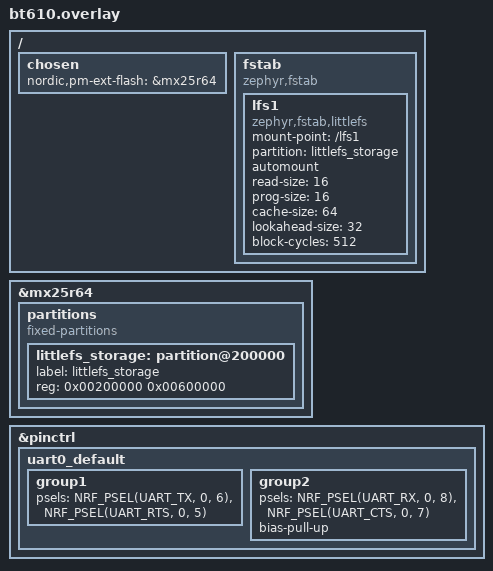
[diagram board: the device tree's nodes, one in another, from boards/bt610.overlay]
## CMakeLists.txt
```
cmake_minimum_required(VERSION 3.13.1)

set(FWK_APP_ID_FILE_LIST
    ${CMAKE_SOURCE_DIR}/src/framework_config/framework_ids_list.h
)

set(FWK_APP_MSG_FILE_LIST
    ${CMAKE_SOURCE_DIR}/src/framework_config/framework_msg_codes_list.h
)
set(mcuboot_CONF_FILE
    ${CMAKE_SOURCE_DIR}/mcuboot_bt610.conf
)
set(mcuboot_ROOT_APP_DIR
    ${CMAKE_SOURCE_DIR}/src
)
set(mcuboot_ROOT_PROJECT_APP_DIR
    ${CMAKE_SOURCE_DIR}
)
set(PM_STATIC_YML_FILE
    ${CMAKE_SOURCE_DIR}/pm_static.sb.bt610.yml
)
set(b0_OVERLAY_CONFIG
    ${CMAKE_SOURCE_DIR}/b0_bt610.conf
)
set(b0_DTC_OVERLAY_FILE
    ${CMAKE_SOURCE_DIR}/boards/bootloader.${BOARD}.overlay
)

set(mcuboot_DTC_OVERLAY_FILE
    ${CMAKE_SOURCE_DIR}/boards/bootloader.${BOARD}.overlay
)

# The component-generated files for attributes
set(ATTR_CUSTOM_PATH_BASE ${CMAKE_SOURCE_DIR}/components/attributes/bt610)

# Version information generation
# Generate build ID based on UTC timestamp
string(TIMESTAMP build_time "%s" UTC)
set(APP_VERSION_BUILD ${build_time})
set(gen_dir ${CMAKE_BINARY_DIR}/zephyr/include/generated/app)
set(ver_file ${gen_dir}/app_version.h)
configure_file(${CMAKE_SOURCE_DIR}/src/version/app_version.h.in ${ver_file})

# Get application version
file(READ ${ver_file} ver)
string(REGEX MATCH "APP_VERSION_MAJOR ([0-9]+)" _ ${ver})
set(ver_major ${CMAKE_MATCH_1})
string(REGEX MATCH "APP_VERSION_MINOR ([0-9]+)" _ ${ver})
set(ver_minor ${CMAKE_MATCH_1})
string(REGEX MATCH "APP_VERSION_PATCH ([0-9]+)" _ ${ver})
set(ver_patch ${CMAKE_MATCH_1})
set(app_version ${ver_major}.${ver_minor}.${ver_patch}+${build_time})
message("app version: ${app_version}")

# Set application version for mcuboot
set(mcuboot_ver_conf ${CMAKE_BINARY_DIR}/generated_mcuboot_image_version.conf)
set(MCUBOOT_IMAGE_VERSION ${app_version})

# This configuration file will get automatically merged when building.
# No need to append to OVERLAY_CONFIG
configure_file(${CMAKE_SOURCE_DIR}/src/version/mcuboot_image_version.conf.in ${mcuboot_ver_conf})

find_package(Zephyr REQUIRED HINTS $ENV{ZEPHYR_BASE})
project(bt610_dm_firmware)

# Build the API
execute_process(
    COMMAND
    ${PYTHON_EXECUTABLE}
    ${CMAKE_SOURCE_DIR}/../modules/lib/laird_connect/attributes/generator/api.py
    ${CMAKE_SOURCE_DIR}
    bt610
    WORKING_DIRECTORY ${CMAKE_SOURCE_DIR}
    RESULT_VARIABLE api_result
)

if(NOT "${api_result}" STREQUAL 0)
    message(FATAL_ERROR "Failed to build API")
endif()

include_directories(${CMAKE_SOURCE_DIR}/include)
include_directories(${CMAKE_SOURCE_DIR}/src/framework_config)
include_directories(${CMAKE_SOURCE_DIR}/src/version)
target_include_directories(app PRIVATE ${gen_dir})
zephyr_include_directories(${CMAKE_SOURCE_DIR}/memfault)

target_sources(app PRIVATE
    ${CMAKE_SOURCE_DIR}/src/AdcBt6.c
    ${CMAKE_SOURCE_DIR}/src/Advertisement.c
    ${CMAKE_SOURCE_DIR}/src/BleTask.c
    ${CMAKE_SOURCE_DIR}/src/BspSupport.c
    ${CMAKE_SOURCE_DIR}/src/ControlTask.c
    ${CMAKE_SOURCE_DIR}/src/EventTask.c
    ${CMAKE_SOURCE_DIR}/src/LEDs.c
    ${CMAKE_SOURCE_DIR}/src/main.c
    ${CMAKE_SOURCE_DIR}/src/NonInit.c
    ${CMAKE_SOURCE_DIR}/src/SensorTask.c
    ${CMAKE_SOURCE_DIR}/src/UserInterfaceTask.c
    ${CMAKE_SOURCE_DIR}/src/Flags.c
    ${ATTR_CUSTOM_PATH_BASE}/src/attr_custom_validator.c
)

if(CONFIG_FS_MGMT_FILE_ACCESS_HOOK)
    target_sources(app PRIVATE
        ${CMAKE_SOURCE_DIR}/src/FileAccess.c
    )
endif()

if(CONFIG_MCUMGR_CMD_PRODUCTION_MGMT)
    target_sources(app PRIVATE
        ${CMAKE_SOURCE_DIR}/src/production_mgmt.c
    )
endif()

if(CONFIG_TEST_MENU)
    target_sources(app PRIVATE
        ${CMAKE_SOURCE_DIR}/src/TestMenu.c
    )
endif()
```

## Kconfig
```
# Copyright (c) 2020 Laird Connectivity
# SPDX-License-Identifier: Apache-2.0

menuconfig USER_APPLICATION
     bool "Config User Application"
	 default y

if USER_APPLICATION

config LAIRD_CONNECTIVITY_DEBUG
    bool
    default n

config JSON_BRACKET_BUFFER_SIZE
    int "The maximum size JSON message that can be processed"
    default 1536
    help
        This applies to sensor messages received over Bluetooth.

config ATTR_SAVE_DELAY_MS
    int "Time (in ms) before saving attributes to filesystem to cache other data to write"
    default 30000
    range 1000 3600000

config UART_SHUTOFF
    bool "Enables shutting the main UART off to conserve power"
    default y

config FILE_ACCESS_LOG_LEVEL
    int "File access log level for reading/writing files over SMP"
    range 0 4
    default 0

config ATTR_SHELL_ALLOW_DEBUG_COMMANDS
    bool "Enables shell functions that can modify, dump and load data"
    help
        This should not be enabled for production builds.

menuconfig MINIMUM_FIRMWARE_VERSION_FOTA_CHECK
    bool "Enable minimum firmware version FOTA check"
    default y

config MINIMUM_FIRMWARE_VERSION_MAJOR
    int "Major firmware version (a.x.x) which is the minimum allowed for FOTA"
    range 0 255
    default 1
    depends on MINIMUM_FIRMWARE_VERSION_FOTA_CHECK

config MINIMUM_FIRMWARE_VERSION_MINOR
    int "Minor firmware version (x.b.x) which is the minimum allowed for FOTA"
    range 0 255
    default 28
    depends on MINIMUM_FIRMWARE_VERSION_FOTA_CHECK

config MINIMUM_FIRMWARE_VERSION_REVISION
    int "Revision firmware version (x.x.c) which is the minimum allowed for FOTA"
    range 0 65535
    default 0
    depends on MINIMUM_FIRMWARE_VERSION_FOTA_CHECK

config MAX_SETTINGS_FILE_SIZE
    int "Maximum size of settings file before removing to save space"
    range 0 4096
    default 1024
    depends on SETTINGS_FS
    help
        A setting of 0 will not purge the file, purge size must be greater than
	256 to be valid.

endif # USER_APPLICATION

rsource "src/Kconfig"

source "Kconfig.zephyr"
```

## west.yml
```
manifest:
  remotes:
    - name: JsmnRepo
      url-base: https://github.com/zserge
    - name: LairdProdEng
      url-base: git@git.devops.rfpros.com:prod_eng
    - name: LairdZephyrPublic
      url-base: git@git.devops.rfpros.com:zephyr_public

  # Please add items below based on alphabetical order.
  # These dependencies may need updating if new features are added to the firmware.
  projects:
    - name: framework_zephyr
      path: modules/framework
      revision: b9a4603436a34d61120b68a10a6cbc74d1e6a3fd
      remote: LairdProdEng
    - name: jsmn
      path: modules/jsmn
      revision: 7b6858a5855299d173c5ab2b46e611bf9961cbef
      remote: JsmnRepo      
    - name: zephyr_boards
      path: zephyr/boards/arm
      revision: master
      remote: LairdZephyrPublic
    - name: zephyr_lib
      path: modules/zephyr_lib
      revision: master
      remote: LairdProdEng      

  self:
    path: root
```

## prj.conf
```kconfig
CONFIG_MCUBOOT_IMAGE_VERSION="2.0.4"

CONFIG_BOOT_BANNER=n

# Enable power management
CONFIG_PM=y
CONFIG_PM_DEVICE=y
CONFIG_PM_DEVICE_RUNTIME=y
CONFIG_PM_DEVICE_RUNTIME_EXCLUSIVE=n

# System stack and heap sizes
CONFIG_SYSTEM_WORKQUEUE_STACK_SIZE=8192
CONFIG_HEAP_MEM_POOL_SIZE=16384
CONFIG_MAIN_STACK_SIZE=4096

# System clock
CONFIG_SYSTEM_CLOCK_WAIT_FOR_STABILITY=y

# Safe reboot
CONFIG_REBOOT=y

# BSP
CONFIG_I2C=y
CONFIG_ADC=y
CONFIG_ADC_NRFX_SAADC=y
CONFIG_GPIO=y

# Floating point support
CONFIG_NEWLIB_LIBC=y
CONFIG_NEWLIB_LIBC_FLOAT_PRINTF=y
# Allow thread-safe FPU for thermistor calculations.
CONFIG_FPU=y
CONFIG_FPU_SHARING=y

# BLE
CONFIG_BT=y
CONFIG_BT_HCI=y
CONFIG_BT_HCI_VS_EXT=y
CONFIG_BT_DEBUG_LOG=n
CONFIG_BT_GAP_PERIPHERAL_PREF_PARAMS=y
CONFIG_BT_PERIPHERAL_PREF_MIN_INT=6
CONFIG_BT_PERIPHERAL_PREF_MAX_INT=150
CONFIG_BT_PERIPHERAL_PREF_LATENCY=2
CONFIG_BT_PERIPHERAL_PREF_TIMEOUT=500
CONFIG_BT_DEVICE_NAME_GATT_WRITABLE=n
CONFIG_BT_SMP=y
CONFIG_BT_MAX_PAIRED=10
CONFIG_BT_PERIPHERAL=y
CONFIG_BT_FIXED_PASSKEY=n
CONFIG_BT_BONDABLE=n
CONFIG_BT_DEVICE_NAME="BT610"
CONFIG_BT_DEVICE_NAME_DYNAMIC=y
# Generic sensor
CONFIG_BT_DEVICE_APPEARANCE=1344
CONFIG_BT_GATT_DYNAMIC_DB=y
CONFIG_BT_REMOTE_VERSION=y
CONFIG_BT_LL_SOFTDEVICE=y
CONFIG_BT_LL_SOFTDEVICE_MULTIROLE=y
CONFIG_BT_MAX_CONN=2
CONFIG_BT_HCI_TX_STACK_SIZE=2048
CONFIG_BT_BUF_ACL_TX_SIZE=251
CONFIG_BT_BUF_ACL_RX_SIZE=260
CONFIG_BT_BUF_EVT_RX_SIZE=255
CONFIG_BT_L2CAP_TX_MTU=260
CONFIG_BT_CTLR_DATA_LENGTH_MAX=251
CONFIG_BT_BUF_ACL_TX_COUNT=5
CONFIG_BT_BUF_ACL_RX_COUNT=5
CONFIG_BT_BUF_EVT_RX_COUNT=5
CONFIG_BT_BUF_EVT_DISCARDABLE_COUNT=5
CONFIG_BT_BUF_CMD_TX_COUNT=5
CONFIG_BT_CONN_TX_MAX=12
CONFIG_BT_L2CAP_TX_BUF_COUNT=12
CONFIG_BT_L2CAP_TX_FRAG_COUNT=3
CONFIG_BT_HCI_TX_STACK_SIZE_WITH_PROMPT=y
CONFIG_BT_HCI_TX_STACK_SIZE=2048
CONFIG_BT_CTLR=y
CONFIG_BT_CTLR_TX_PWR_PLUS_8=y
CONFIG_BT_CTLR_TX_PWR_DYNAMIC_CONTROL=y
# Allow Coded PHY (requires Nordic Bluetooth host)
CONFIG_BT_CTLR_PHY_CODED=y
CONFIG_BT_EXT_ADV=y
CONFIG_BT_CTLR_ADV_EXT=y
CONFIG_BT_USER_PHY_UPDATE=y
# Nordic Softdevice configuration
CONFIG_BT_CTLR_SDC_RX_STACK_SIZE=2048
CONFIG_BT_CTLR_SDC_MAX_CONN_EVENT_LEN_DEFAULT=820000
# Disable auto DLE due to bug with pre-4.2 devices - Bug #19725
CONFIG_BT_AUTO_DATA_LEN_UPDATE=n
# Additions for DM
CONFIG_BT_GATT_CLIENT=y
CONFIG_BT_GATT_DM=y
CONFIG_BT_DFU_SMP=y
CONFIG_BT_USER_DATA_LEN_UPDATE=y
CONFIG_BT_RX_STACK_SIZE=4096

# Console
CONFIG_LOG=y
CONFIG_LOG_DEFAULT_LEVEL=4
CONFIG_LOG_BUFFER_SIZE=4096
CONFIG_LOG_PROCESS_THREAD_STACK_SIZE=4096
CONFIG_LOG_SPEED=y
CONFIG_LOG_TRACE_SHORT_TIMESTAMP=n
CONFIG_LOG_TIMESTAMP_64BIT=y
CONFIG_LOG_BACKEND_FS=y
CONFIG_LOG_BACKEND_FS_DIR="/lfs1/logs"
CONFIG_LOG_BACKEND_FS_FILE_SIZE=128000
CONFIG_LOG_BACKEND_FS_FILES_LIMIT=8

# Command line shell
CONFIG_SHELL=y
CONFIG_SHELL_HISTORY=n
CONFIG_KERNEL_SHELL=y
CONFIG_SHELL_STACK_SIZE=3072
CONFIG_SHELL_THREAD_PRIORITY_OVERRIDE=y
# Change priority to be higher than logging thread to avoid log messages not showing at boot
CONFIG_SHELL_THREAD_PRIORITY=13
CONFIG_DEVMEM_SHELL=n
CONFIG_FLASH_SHELL=n
CONFIG_LCZ_SHELL_LOGIN=y
CONFIG_SHELL_LOGIN_INIT_PRIORITY=75
CONFIG_SHELL_LOGIN_INIT_USING_ATTRIBUTES=y
CONFIG_SHELL_PROMPT_UART="login: "
CONFIG_SHELL_CMD_ROOT="login"
CONFIG_LCZ_SHELL_SCRIPT_RUNNER=y
CONFIG_SHELL_BACKEND_DUMMY=y

# LCZ Message Framework
CONFIG_FRAMEWORK=y
CONFIG_FWK_ASSERT_ENABLED=y
CONFIG_FWK_AUTO_GENERATE_FILES=y
CONFIG_BUFFER_POOL_SIZE=16384
CONFIG_BUFFER_POOL_STATS=y
CONFIG_BUFFER_POOL_SHELL=y
CONFIG_SYSTEM_MESSAGE_TASK=y

# Flash storage
CONFIG_MPU_ALLOW_FLASH_WRITE=y
CONFIG_FLASH=y
CONFIG_FLASH_PAGE_LAYOUT=y
CONFIG_FLASH_MAP=y

# Device settings
CONFIG_SETTINGS=y
# Prefix must match CONFIG_SETTINGS_MOUNT_POINT
CONFIG_SETTINGS_MOUNT_POINT="/lfs1"
CONFIG_SETTINGS_FS_DIR="/lfs1/settings"
CONFIG_SETTINGS_FS_FILE="/lfs1/settings/run"

# QSPI (MX25R64)
CONFIG_NORDIC_QSPI_NOR=y
CONFIG_NORDIC_QSPI_NOR_FLASH_LAYOUT_PAGE_SIZE=4096
CONFIG_NORDIC_QSPI_NOR_STACK_WRITE_BUFFER_SIZE=16

# MCUBOOT
CONFIG_BOOTLOADER_MCUBOOT=y
CONFIG_SECURE_BOOT=y
CONFIG_BUILD_S1_VARIANT=y
CONFIG_NRF_APPROTECT_LOCK=y
CONFIG_LCZ_APPROTECT=y
CONFIG_MCUBOOT_IMG_MANAGER=y
# Turn off for development
# Bug 22277 - Remove comment around CONFIG_LCZ_APPROTECT_STARTUP
# CONFIG_LCZ_APPROTECT_STARTUP=y

# MCUMGR
CONFIG_MCUMGR=y
CONFIG_MCUMGR_SMP_SHELL=y
CONFIG_MCUBOOT_SHELL_ERASE_ENABLED=n
CONFIG_MCUMGR_SMP_SHELL_MTU=512
CONFIG_MCUMGR_SMP_SHELL_RX_BUF_COUNT=4
CONFIG_MCUMGR_BUF_SIZE=1210
CONFIG_MCUMGR_BUF_COUNT=8
# Enable the Bluetooth (unauthenticated) mcumgr transport.
CONFIG_MCUMGR_SMP_BT=y
CONFIG_MCUMGR_CMD_IMG_MGMT=y
CONFIG_MCUMGR_CMD_OS_MGMT=y
CONFIG_MCUMGR_CMD_PRODUCTION_MGMT=y
CONFIG_STATS=y
CONFIG_MCUMGR_CMD_STAT_MGMT=y
CONFIG_MCUMGR_CMD_SHELL_MGMT=y
CONFIG_OS_MGMT_MCUMGR_PARAMS=y
CONFIG_MCUMGR_SMP_REASSEMBLY_BT=y

# File system
# Enable the LittleFS file system.
CONFIG_FILE_SYSTEM=y
CONFIG_FILE_SYSTEM_LITTLEFS=y
CONFIG_FILE_SYSTEM_UTILITIES=y
CONFIG_FSU_MOUNT_POINT="/lfs1"
CONFIG_FSU_LOG_LEVEL=3
CONFIG_FILE_SYSTEM_MAX_FILE_NAME=64
CONFIG_FSU_SHELL_ALLOW_CHANGE=n
CONFIG_FSU_CHECKSUM=y
CONFIG_FSU_CHECKSUM_CHUNK_SIZE=512
CONFIG_FSU_ENCRYPTED_FILES=y
CONFIG_FILE_ACCESS_LOG_LEVEL=3
CONFIG_FSU_ENCRYPTED_FILES_INIT_PRIORITY=65
CONFIG_LCZ_MCUMGR_CMD_FS_MGMT=y
CONFIG_LCZ_FS_MGMT_MAX_FILE_SIZE_4GB=y
CONFIG_LCZ_FS_MGMT_FILE_ACCESS_HOOK=y
CONFIG_LCZ_FS_MGMT_CHECKSUM_HASH=y
CONFIG_LCZ_FS_MGMT_HASH_SHA256=y
CONFIG_FSU_HASH=y
CONFIG_FILE_SYSTEM_SHELL=y

# Security
CONFIG_NRF_SECURITY=y

# MBEDTLS
CONFIG_MBEDTLS=y
CONFIG_MBEDTLS_BUILTIN=n
CONFIG_MBEDTLS_TLS_LIBRARY=y
CONFIG_MBEDTLS_LEGACY_CRYPTO_C=y
CONFIG_MBEDTLS_SSL_IN_CONTENT_LEN=4096
CONFIG_MBEDTLS_SSL_OUT_CONTENT_LEN=4096
CONFIG_MBEDTLS_ENABLE_HEAP=y
CONFIG_MBEDTLS_HEAP_SIZE=16384
# Disable unused ciphers.
# NOTE: Commented lines below mean we are allowing those ciphers
CONFIG_MBEDTLS_KEY_EXCHANGE_PSK_ENABLED=n
CONFIG_MBEDTLS_KEY_EXCHANGE_DHE_PSK_ENABLED=n
CONFIG_MBEDTLS_KEY_EXCHANGE_ECDHE_PSK_ENABLED=n
CONFIG_MBEDTLS_KEY_EXCHANGE_RSA_PSK_ENABLED=n
CONFIG_MBEDTLS_KEY_EXCHANGE_RSA_ENABLED=n
CONFIG_MBEDTLS_KEY_EXCHANGE_DHE_RSA_ENABLED=n
CONFIG_MBEDTLS_KEY_EXCHANGE_ECDHE_RSA_ENABLED=n
# CONFIG_MBEDTLS_KEY_EXCHANGE_ECDHE_ECDSA_ENABLED=n
# CONFIG_MBEDTLS_KEY_EXCHANGE_ECDH_ECDSA_ENABLED=n
CONFIG_MBEDTLS_KEY_EXCHANGE_ECDH_RSA_ENABLED=n
CONFIG_MBEDTLS_KEY_EXCHANGE_ECJPAKE_ENABLED=n
# Disable CBC, it is not secure
CONFIG_PSA_WANT_ALG_CBC_NO_PADDING=n
CONFIG_PSA_WANT_ALG_CBC_PKCS7=n
CONFIG_MBEDTLS_CIPHER_MODE_CBC=n
# Disable unused hash algorithms
CONFIG_PSA_WANT_ALG_SHA_384=n
CONFIG_PSA_WANT_ALG_SHA_512=n
CONFIG_PSA_WANT_ALG_MD5=n
CONFIG_MBEDTLS_SHA384_C=n
CONFIG_MBEDTLS_SHA512_C=n

# LCZ modules
CONFIG_LCZ=y

# LCZ BLE wrapper
CONFIG_LCZ_BT=y

# LCZ QRTC
CONFIG_LCZ_QRTC=y
CONFIG_LCZ_QRTC_SHELL=y
CONFIG_LCZ_QRTC_SHELL_ENABLE_WRITE=n

# LCZ Exit override
CONFIG_LCZ_RESET_ON_EXIT=y

# LCZ Param file
CONFIG_LCZ_PARAM_FILE=y
CONFIG_LCZ_PARAM_FILE_ENCRYPTED=y
CONFIG_LCZ_SENSOR_ADV_FORMAT=y
CONFIG_LCZ_MCUMGR_WRAPPER=y
CONFIG_LCZ_NO_INIT_RAM_VAR=y
CONFIG_ATTRIBUTE_MGMT_FACTORY_RESET=y

# LCZ LED module
CONFIG_LCZ_LED=y
CONFIG_LCZ_NUMBER_OF_LEDS=2
CONFIG_LCZ_LED_CUSTOM_ON_OFF=n

# LCZ Watchdog support
CONFIG_WATCHDOG=y
CONFIG_WDT_NRFX=y
CONFIG_NRFX_WDT0=y
CONFIG_LCZ_WDT=y

# LCZ reset reason utility
CONFIG_LCZ_NRF_RESET_REASON=y

# LCZ Attributes
CONFIG_LCZ_KVP=y
CONFIG_ATTR=y
CONFIG_ATTR_BROADCAST=y
CONFIG_ATTR_ENCRYPTED=y
CONFIG_ATTR_SHELL=y
CONFIG_ATTR_DEFERRED_SAVE=y
CONFIG_MCUMGR_CMD_ATTRIBUTE_MGMT=y
CONFIG_ATTR_LOAD_FEEDBACK=y
CONFIG_ATTR_CUSTOM_VALIDATOR=y
CONFIG_ATTR_SHELL=y
CONFIG_ATTR_SHOW_FMT="[%03u] %-35s"
CONFIG_ATTR_FILE_NAME="enc/attr.txt"

# LCZ hardware unique key
CONFIG_HW_UNIQUE_KEY=y
CONFIG_HW_UNIQUE_KEY_RANDOM=y
CONFIG_LCZ_HW_KEY=y

# LCZ Locking component
CONFIG_LOCKING=y

# LCS Software Reset management
CONFIG_LCZ_SOFTWARE_RESET=y

# zcbor
CONFIG_ZCBOR=y

# Thread Debug
CONFIG_THREAD_NAME=y
CONFIG_THREAD_MAX_NAME_LEN=16
CONFIG_INIT_STACKS=y
CONFIG_THREAD_ANALYZER=y

# Stack protection options that should always be enabled
CONFIG_MPU_STACK_GUARD=y

# Debug options that should be enabled for debugging
CONFIG_ASSERT=n
CONFIG_STACK_SENTINEL=n
CONFIG_EXTRA_EXCEPTION_INFO=y
CONFIG_NULL_POINTER_EXCEPTION_DETECTION_MPU=y
CONFIG_USE_SEGGER_RTT=y

# Application level options
CONFIG_LOG_LEVEL_BLE_TASK=3
CONFIG_UI_TASK_LOG_LEVEL=3
CONFIG_BSP_LOG_LEVEL=3
CONFIG_UI_LED_TEST_ON_RESET=y
CONFIG_TEST_MENU=y
CONFIG_HEARTBEAT_SECONDS=60
CONFIG_SENSOR_TASK_LOG_LEVEL=3

# PKI authentication and management
CONFIG_LCZ_PKI_AUTH=y
CONFIG_LCZ_PKI_AUTH_SMP_PERIPHERAL=y
CONFIG_LCZ_SENSOR_ADV_ENC=y

# LWM2M
CONFIG_EVENTFD=y
CONFIG_LWM2M=y
CONFIG_LWM2M_LOG_LEVEL_INF=y
CONFIG_HTTP_PARSER_URL=y
CONFIG_LWM2M_COAP_BLOCK_SIZE=512
CONFIG_LWM2M_ENGINE_STACK_SIZE=8192
# LwM2M lifetime of 10 minutes instead of 30 seconds
CONFIG_LWM2M_ENGINE_DEFAULT_LIFETIME=600
# Observation notifications normally no faster than every minute
CONFIG_LWM2M_SERVER_DEFAULT_PMIN=60

# Client device manager
CONFIG_LCZ_BLE_CLIENT_DM=y
CONFIG_LCZ_BLE_CLIENT_DM_INIT_ATTRIBUTES=y
CONFIG_LCZ_BLE_CLIENT_CONTROL_QRTC=y

# Main LwM2M Client
CONFIG_LCZ_LWM2M_CLIENT=y
CONFIG_LCZ_LWM2M_CLIENT_LOG_LEVEL_DBG=y
CONFIG_LCZ_LWM2M_CLIENT_INIT_ATTRIBUTES=y
CONFIG_LCZ_LWM2M_CLIENT_DEVICE_INIT_ATTRIBUTES=y
CONFIG_LCZ_LWM2M_TRANSPORT_BLE_PERIPHERAL=y
CONFIG_LCZ_LWM2M_TRANSPORT_BLE_MAX_PACKET=1200
CONFIG_LCZ_LWM2M_CLIENT_SHELL=y

# Firmware update
CONFIG_LCZ_LWM2M_FW_UPDATE=y
CONFIG_LWM2M_SWMGMT_PACKAGE_URI_LEN=256
CONFIG_DFU_TARGET=y
CONFIG_IMG_ERASE_PROGRESSIVELY=y
CONFIG_LCZ_LWM2M_FW_UPDATE_INIT_ATTRIBUTES=y
CONFIG_LWM2M_FIRMWARE_UPDATE_PULL_COAP_PROXY_SUPPORT=y
CONFIG_LCZ_LWM2M_FW_UPDATE_SHELL=y

# File system management
CONFIG_LCZ_LWM2M_FS_MANAGEMENT=y

# Connection Monitor
CONFIG_LCZ_LWM2M_CONN_MON=y
CONFIG_LWM2M_CONN_MON_BEARER_MAX=2

# Networking
CONFIG_NETWORKING=y
CONFIG_NET_NATIVE=n
CONFIG_NET_IPV6=n

# LwM2M Telemetry Configuration
CONFIG_LWM2M_IPSO_SUPPORT=y
CONFIG_LCZ_LWM2M_UTIL=y
CONFIG_LCZ_LWM2M_UTIL_CONFIG_DATA=y
CONFIG_LCZ_LWM2M_UTIL_LOG_LEVEL_DBG=y
CONFIG_LCZ_LWM2M_TEMPERATURE=y
CONFIG_LWM2M_IPSO_TEMP_SENSOR=y
CONFIG_LWM2M_IPSO_TEMP_SENSOR_INSTANCE_COUNT=4
CONFIG_LCZ_LWM2M_FILL_LEVEL=y
CONFIG_LWM2M_IPSO_FILLING_SENSOR=y
CONFIG_LWM2M_IPSO_FILLING_SENSOR_INSTANCE_COUNT=4
CONFIG_LCZ_LWM2M_CURRENT=y
CONFIG_LWM2M_IPSO_CURRENT_SENSOR=y
CONFIG_LWM2M_IPSO_CURRENT_SENSOR_INSTANCE_COUNT=4
CONFIG_LCZ_LWM2M_PRESSURE=y
CONFIG_LWM2M_IPSO_PRESSURE_SENSOR=y
CONFIG_LWM2M_IPSO_PRESSURE_SENSOR_INSTANCE_COUNT=4
```

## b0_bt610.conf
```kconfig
# WARNING: To maintain the integrity of secure boot,
# enable CONFIG_DISABLE_FLASH_PATCH in production.
# CONFIG_DISABLE_FLASH_PATCH=y
CONFIG_HW_UNIQUE_KEY_LOAD=y
CONFIG_RESET_ON_FATAL_ERROR=n
CONFIG_REBOOT=y
CONFIG_I2C=n

CONFIG_SECURE_BOOT_DEBUG=n
CONFIG_CONSOLE=n
CONFIG_UART_CONSOLE=n
CONFIG_BOOT_BANNER=n
CONFIG_LOG=n

CONFIG_HW_STACK_PROTECTION=n
```

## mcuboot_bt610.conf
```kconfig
# Laird Connectivity BT6 mcuboot configuration
# Enables CC310 with ECDSA-p256 and no debugging
CONFIG_BOOT_VALIDATE_SLOT0=y

CONFIG_SIZE_OPTIMIZATIONS=y

CONFIG_BOOT_BANNER=n

CONFIG_CONSOLE_HANDLER=n
CONFIG_DEBUG=n

CONFIG_MAIN_STACK_SIZE=10240
CONFIG_MBEDTLS_CFG_FILE="mcuboot-mbedtls-cfg.h"

# Do not erase all flash when flashing mcuboot
CONFIG_ZEPHYR_TRY_MASS_ERASE=n

### Default to ECDSA
CONFIG_BOOT_SIGNATURE_TYPE_ECDSA_P256=y
CONFIG_BOOT_ECDSA_CC310=y
CONFIG_BOOT_SIGNATURE_KEY_FILE="root-ec-p256.pem"
CONFIG_NRF_CC310_BL=y

### We never want Zephyr's copy of tinycrypt.  If tinycrypt is needed,
### MCUboot has its own copy in tree.
# CONFIG_TINYCRYPT is not set
# CONFIG_TINYCRYPT_ECC_DSA is not set
# CONFIG_TINYCRYPT_SHA256 is not set

CONFIG_FLASH=y

# nrf52840 with QSPI
CONFIG_MULTITHREADING=y
CONFIG_NORDIC_QSPI_NOR=y
CONFIG_NORDIC_QSPI_NOR_FLASH_LAYOUT_PAGE_SIZE=4096
CONFIG_NORDIC_QSPI_NOR_STACK_WRITE_BUFFER_SIZE=16
CONFIG_BOOT_MAX_IMG_SECTORS=256
CONFIG_MPU_ALLOW_FLASH_WRITE=y

CONFIG_BOOT_SWAP_USING_MOVE=y
CONFIG_BOOT_BANNER=n
CONFIG_SERIAL=n
CONFIG_CONSOLE=n
CONFIG_UART_CONSOLE=n
CONFIG_STDOUT_CONSOLE=n
CONFIG_PRINTK=n
CONFIG_EARLY_CONSOLE=n
CONFIG_ASSERT_VERBOSE=n

CONFIG_LCZ=y
CONFIG_LCZ_NO_INIT_RAM_VAR=y
CONFIG_LCZ_LED=y
CONFIG_LCZ_NUMBER_OF_LEDS=2

# WARNING: To maintain the integrity of secure boot,
# enable CONFIG_DISABLE_FLASH_PATCH in production.
# Bug 22275 - enable CONFIG_DISABLE_FLASH_PATCH
# CONFIG_DISABLE_FLASH_PATCH=y
CONFIG_FW_INFO=y
# set mcuboot version
CONFIG_FW_INFO_FIRMWARE_VERSION=1
CONFIG_RESET_ON_FATAL_ERROR=n
CONFIG_REBOOT=y
```

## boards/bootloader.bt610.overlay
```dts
/delete-node/ &uart1;
```

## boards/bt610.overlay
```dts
/*
 * Copyright (c) 2021 Nordic Semiconductor ASA
 * Copyright (c) 2022 Laird Connectivity LLC
 *
 * SPDX-License-Identifier: LicenseRef-Nordic-5-Clause
 */

/delete-node/ &lfs_partition;

/ {
	chosen {
		/* required for partition manager to use external flash */
		nordic,pm-ext-flash = &mx25r64;
	};

	fstab {
		compatible = "zephyr,fstab";
		lfs1: lfs1 {
			compatible = "zephyr,fstab,littlefs";
			mount-point = "/lfs1";
			partition = <&littlefs_storage>;
			automount;
			read-size = <16>;
			prog-size = <16>;
			cache-size = <64>;
			lookahead-size = <32>;
			block-cycles = <512>;
		};
	};
};

&mx25r64 {
	partitions {
		compatible = "fixed-partitions";
		#address-cells = <1>;
		#size-cells = <1>;

		littlefs_storage: partition@200000 {
			label = "littlefs_storage";
			reg = <0x00200000 0x00600000>;
		};
	};
};

/delete-node/ &uart1;
/delete-node/ &uart0_default;

&pinctrl {
	uart0_default: uart0_default {
		group1 {
			psels = <NRF_PSEL(UART_TX, 0, 6)>,
					<NRF_PSEL(UART_RTS, 0, 5)>;
		};
		group2 {
			psels = <NRF_PSEL(UART_RX, 0, 8)>,
					<NRF_PSEL(UART_CTS, 0, 7)>;
			bias-pull-up;
		};
	};
};
```

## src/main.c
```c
/* main.c - Application main entry point */

/*
 * Copyright (c) 2019-2023 Laird Connectivity
 *
 * SPDX-License-Identifier: Apache-2.0
 */
#include <zephyr/logging/log.h>
LOG_MODULE_REGISTER(main, LOG_LEVEL_DBG);
#include <zephyr/zephyr.h>
#include <version.h>
#ifdef CONFIG_ATTR
#include <attr.h>
#endif
#ifdef CONFIG_LCZ_LWM2M_CLIENT
#include <lcz_lwm2m_client.h>
#endif
#ifdef CONFIG_LCZ_LWM2M_FW_UPDATE
#include <lcz_lwm2m_fw_update.h>
#endif
#include "app_version.h"
#ifdef CONFIG_SHELL_BACKEND_SERIAL
#include <zephyr/shell/shell_uart.h>
#endif
#include <zephyr/drivers/uart.h>
#include "ControlTask.h"
#include "BspSupport.h"

/**************************************************************************************************/
/* Local Constant, Macro and Type Definitions                                                     */
/**************************************************************************************************/
#define PKG_NAME_PREFIX "lc_dm"
#define PKG_NAME PKG_NAME_PREFIX "-" CONFIG_BOARD "-"

void main(void)
{
#ifdef CONFIG_SHELL_BACKEND_SERIAL
	/* Disable log output by default on the UART console.
	 * Re-enable logging using the 'log go' cmd.
	 * LCZ_SHELL_LOGIN selects SHELL_START_OBSCURED which disables log output before main().
	 */
#ifdef CONFIG_ATTR
	if (attr_get_bool(ATTR_ID_log_on_boot) == false)
#endif
	{
		log_backend_deactivate(shell_backend_uart_get_ptr()->log_backend->backend);
	}
#endif

#ifdef CONFIG_LCZ_LWM2M_CLIENT
	(void)lcz_lwm2m_client_set_device_firmware_version(APP_VERSION_STRING);
	(void)lcz_lwm2m_client_set_software_version(KERNEL_VERSION_STRING);
#endif
#ifdef CONFIG_LCZ_LWM2M_FW_UPDATE
	(void)lcz_lwm2m_fw_update_set_pkg_name(PKG_NAME);
#endif
	BSP_Init();
	ControlTask_Initialize();
	ControlTask_Thread();

	LOG_INF("BT610 DM Firmware v%s [%s]", APP_VERSION_STRING, CONFIG_BOARD);
}
```

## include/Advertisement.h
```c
/**
 * @file Advertisement.h
 * @brief
 *
 * Copyright (c) 2020 Laird Connectivity
 *
 * SPDX-License-Identifier: Apache-2.0
 */
#ifndef __ADVERTISEMENT_H__
#define __ADVERTISEMENT_H__

/******************************************************************************/
/* Includes                                                                   */
/******************************************************************************/

#ifdef __cplusplus
extern "C" {
#endif

/******************************************************************************/
/* Global Constants, Macros and Type Definitions                              */
/******************************************************************************/
typedef struct {
	SensorEvent_t event;
	uint32_t id;
} SensorMsg_t;

/******************************************************************************/
/* Global Data Definitions                                                    */
/******************************************************************************/

/******************************************************************************/
/* Global Function Prototypes                                                 */
/******************************************************************************/
/**
 * @brief Setup of the different advertisment PHY types
 */
int Advertisement_Init(void);

/**
 * @brief Stops the device from advertising 
 */
int Advertisement_End(void);

/**
 * @brief Starts advertising with the PHY that is enabled
 */
int Advertisement_Start(void);

/**
 * @brief Will force the the coded PHY(Extended advertisment) to begin 
 *  when status is set to true
 *
 * @param status This will enable or disable the coded PHY
 */
void Advertisement_ExtendedSet(bool status);

/**
 * @brief This function will update bytes that have changed in advertisment
 *
 * @param sensor_event There are fields in the advert for events, and this is that data
 *
 * @retval negative error code, 0 on success
 */
int Advertisement_Update(SensorMsg_t *sensor_event);

/**
 * @brief The advertisment interval has been set elsewhere and needs 
 * parameter changed and read from the attribute
 *
 * @retval negative error code, 0 on success
 */
int Advertisement_IntervalUpdate(void);

/**
 * @brief This will set the interval back to what default was and 
 * not change interval attribute
 *
 * @retval negative error code, 0 on success
 */
int Advertisement_IntervalDefault(void);

/**
 * @brief This is only used for the test menue to create a simulated event
 *
 * @param status event number that will be created
 */
void TestEventMsg(uint16_t event);

#ifdef __cplusplus
}
#endif

#endif /* __ADVERTISEMENT_H__ */
```

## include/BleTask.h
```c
/**
 * @file BleTask.h
 * @brief
 *
 * Copyright (c) 2020 Laird Connectivity
 *
 * SPDX-License-Identifier: Apache-2.0
 */
#ifndef __BLE_TASK_H__
#define __BLE_TASK_H__

/******************************************************************************/
/* Includes                                                                   */
/******************************************************************************/
#include <zephyr/types.h>
#include <stddef.h>

#ifdef __cplusplus
extern "C" {
#endif

/******************************************************************************/
/* Global Constants, Macros and Type Definitions                              */
/******************************************************************************/

/******************************************************************************/
/* Global Data Definitions                                                    */
/******************************************************************************/

/******************************************************************************/
/* Global Function Prototypes                                                 */
/******************************************************************************/
/**
 * @brief
 *
 * @param
 * @param
 *
 * @retval
 */
void BleTask_Initialize(void);

/**
 * @brief Returns if there is an active connection
 *
 * @retval true if there is an active connection, false otherwise
 */
bool ble_is_connected(void);

/**
 * @brief Returns if the last connection was made used coded PHY
 *
 * @retval true if LE coded, false otherwise
 */
bool ble_conn_last_was_le_coded(void);

#ifdef __cplusplus
}
#endif

#endif /* __BLE_TASK_H__ */
```

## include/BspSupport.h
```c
/**
 * @file BspSupport.h
 *
 * Copyright (c) 2020-2023 Laird Connectivity
 *
 * SPDX-License-Identifier: Apache-2.0
 */
#ifndef __BSP_SUPPORT_H__
#define __BSP_SUPPORT_H__

/******************************************************************************/
/* Includes                                                                   */
/******************************************************************************/
#include <zephyr/types.h>
#include <stddef.h>
#include <zephyr/drivers/gpio.h>

#ifdef __cplusplus
extern "C" {
#endif

/******************************************************************************/
/* Global Constants, Macros and Type Definitions                              */
/******************************************************************************/
/* clang-format off */
/* Inputs */
#define UART_0_CTS_PIN (7)  /* SIO_7  Port0 */
#define DIN1_MCU_PIN   (9)  /* SIO_09 Port0 */
#define DIN2_MCU_PIN   (43) /* SIO_43 Port1 */
#define MAGNET_MCU_PIN (47) /* SIO_47 Port1 */
#define UART_0_RXD_PIN (5)  /* SIO_05 Port0 */
#define SW1_PIN        (24) /* SIO_24 Port0 */
#define SW2_PIN        (33) /* SIO_33 Port1 */

/* Digital Input pin masks - combined in the digitalInput attribute */
#define DIN1_PIN_MASK 0x1
#define DIN2_PIN_MASK 0x2

/* Outputs */
/* PORT0 */
#define UART_0_RTS_PIN       (5)  /* SIO_05 Port0 */
#define THERM_ENABLE_PIN     (10) /* SIO_10 Port0 */
#define DO2_PIN              (11) /* SIO_11 Port0 */
#define DO1_PIN              (12) /* SIO_12 Port0 */
#define BATT_OUT_ENABLE_PIN  (30) /* SIO_30 Port0 */
/* PORT1 */
#define DIN1_ENABLE_PIN      (37) /* SIO_37 Port1 */
#define FIVE_VOLT_ENABLE_PIN (44) /* SIO_44 Port1 */
#define DIN2_ENABLE_PIN      (42) /* SIO_42 Port1 */
#define ANALOG_ENABLE_PIN    (45) /* SIO_45 Port1 */
/* clang-format on */

#define GPIO_PER_PORT 32
#define GPIO_PIN_MAX 47

#define GPIO_PIN_MAP(p) ((p > GPIO_PER_PORT) ? (p - GPIO_PER_PORT) : p)

/******************************************************************************/
/* Global Data Definitions                                                    */
/******************************************************************************/

/******************************************************************************/
/* Global Function Prototypes                                                 */
/******************************************************************************/
/**
 * @brief
 *
 * @param
 * @param
 *
 * @retval
 */
void BSP_Init(void);
int BSP_PinSet(uint8_t pin, int value);
int BSP_PinToggle(uint8_t pin);
int BSP_PinGet(uint8_t pin);
void BSP_DigitalPinsStatus(void);
void BSP_ConfigureDigitalInputs(uint8_t pin, gpio_flags_t enable,
				gpio_flags_t edge);
int BSP_UpdateDigitalInput1SimulatedStatus(bool simulation_enabled,
					   bool last_simulation_enabled);
int BSP_UpdateDigitalInput2SimulatedStatus(bool simulation_enabled,
					   bool last_simulation_enabled);
int BSP_UpdateDigitalInput1SimulatedValue(bool simulated_value,
					  bool last_simulated_value);
int BSP_UpdateDigitalInput2SimulatedValue(bool simulated_value,
					  bool last_simulated_value);
#ifdef __cplusplus
}
#endif

#endif /* __BSP_SUPPORT_H__ */
```

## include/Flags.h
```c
/**
 * @file Flags.h
 * @brief
 *
 * Copyright (c) 2020 Laird Connectivity
 *
 * SPDX-License-Identifier: Apache-2.0
 */
#ifndef __FLAGS_H__
#define __FLAGS_H__

/******************************************************************************/
/* Includes                                                                   */
/******************************************************************************/

#ifdef __cplusplus
extern "C" {
#endif

/******************************************************************************/
/* Global Constants, Macros and Type Definitions                              */
/******************************************************************************/
#define FLAG_DEVICE_MANAGEMENT_DATA_READY    0x1, 0
#define FLAG_MEMFAULT_DATA                   0x1, 1
#define FLAG_TIME_WAS_SET                    0x1, 2
#define FLAG_ACTIVE_MODE                     0x1, 3
#define FLAG_LOW_BATTERY_ALARM               0x1, 4
#define FLAG_DIGITAL_IN1_STATE               0x1, 5
#define FLAG_DIGITAL_IN2_STATE               0x1, 6
#define FLAG_TAMPER_SWITCH_STATE             0x1, 7
#define FLAG_MAGNET_STATE                    0x1, 8
#define FLAG_UNUSED_0                        0x1, 9
#define FLAG_UNUSED_1                        0x1, 10
#define FLAG_UNUSED_2                        0x1, 11
#define FLAG_UNUSED_3                        0x1, 12
#define FLAG_UNUSED_4                        0x1, 13
#define FLAG_UNUSED_5                        0x1, 14
#define FLAG_UNUSED_6                        0x1, 15

/******************************************************************************/
/* Global Data Definitions                                                    */
/******************************************************************************/

/******************************************************************************/
/* Global Function Prototypes                                                 */
/******************************************************************************/
//-----------------------------------------------
//! @brief  This module uses a mutex.
//!
void Flags_Init(void);

//-----------------------------------------------
//! @brief  Set a single or multi-bit flag.  Handles setting of any alarm flag based upon
//! ANY_ALARM_MASK.
//!
void Flags_Set(uint32_t Mask, uint32_t Position, uint32_t Value);

//-----------------------------------------------
//! @retval The current value of the flags.
//!
uint32_t Flags_Get(void);

#ifdef __cplusplus
}
#endif

#endif /* __FLAGS_H__ */
```

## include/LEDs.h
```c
/**
 * @file LEDs.h
 * @brief
 *
 * Copyright (c) 2021 Laird Connectivity
 *
 * SPDX-License-Identifier: Apache-2.0
 */
#ifndef __LEDS_H__
#define __LEDS_H__

/******************************************************************************/
/* Includes                                                                   */
/******************************************************************************/

#ifdef __cplusplus
extern "C" {
#endif

typedef enum {
        LED_COLOR_RED = 0,
        LED_COLOR_GREEN,
        LED_COLOR_AMBER,
        LED_COLOR_NONE
} ledColors_t;

typedef enum {
        LED_PATTERN_TAMPER = 0,
        LED_PATTERN_ALIVE,
        LED_PATTERN_EXIT_SHELF_MODE,
        LED_PATTERN_FACTORY_RESET,
        LED_PATTERN_BOOTLOADER_ACTIVE,
#if defined(CONFIG_LCZ_LWM2M_TRANSPORT_BLE_PERIPHERAL)
        LED_PATTERN_DM_CONNECTED
#endif
} ledPatterns_t;

/******************************************************************************/
/* Global Function Prototypes                                                 */
/******************************************************************************/
/**
 * @brief Initialises the LEDs as outputs (off)
 */
void InitialiseLEDs(void);

/**
 * @brief Run LED test
 *
 * @param duration of each step in milliseconds
 */
void led_test(uint32_t delay);

/**
 * @brief Blinks LEDs in pattern
 *
 * @param LED(s) to use
 * @param pattern to use
 */
void led_blink(ledColors_t color, ledPatterns_t pattern);

/**
 * @brief Turns LEDs on
 *
 * @param LED(s) to use
 */
void led_on(ledColors_t color);

/**
 * @brief Turns LEDs off
 *
 * @param LED(s) to use
 */
void led_off(ledColors_t color);

#ifdef __cplusplus
}
#endif

#endif /* __LEDS_H__ */
```

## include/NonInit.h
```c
/**
 * @file NonInit.h
 * @brief
 *
 * Copyright (c) 2021 Laird Connectivity
 *
 * SPDX-License-Identifier: Apache-2.0
 */
#ifndef __NON_INIT_H__
#define __NON_INIT_H__

#include <zephyr/types.h>
#include <stdbool.h>

#include "NonInitStruct.h"

#ifdef __cplusplus
extern "C" {
#endif

/******************************************************************************/
/* Global Function Prototypes                                                 */
/******************************************************************************/
#if defined(CONFIG_MCUBOOT)
/**
 * @brief Saves bootloader start up time to non-init RAM section and updates
 * the header
 *
 * @param Run time of mcuboot in ms
 */
void non_init_set_bootloader_time(uint32_t time);
#else
/**
 * @brief Saves epoch to non-init RAM section and upates the header
 */
void non_init_save_data(void);

/**
 * @brief Sets the unsaved data present flag to be set or unset and saves this
 * to the non-initialised area in RAM
 *
 * @param true if there is pending unsaved data, false otherwide
 */
void non_init_set_save_flag(bool status);
/**
 * @brief Saves epoch of zero to non-init RAM section and upates the header
 */
void non_init_clear_qrtc(void);
#endif

#ifdef __cplusplus
}
#endif

#endif /* __NON_INIT_H__ */
```

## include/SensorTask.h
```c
/**
 * @file SensorTask.h
 * @brief
 *
 * Copyright (c) 2020-2021 Laird Connectivity
 *
 * SPDX-License-Identifier: Apache-2.0
 */
#ifndef __SENSOR_TASK_H__
#define __SENSOR_TASK_H__

/******************************************************************************/
/* Includes                                                                   */
/******************************************************************************/
#include <zephyr/types.h>
#include <stddef.h>
#include <drivers/spi.h>

#ifdef __cplusplus
extern "C" {
#endif

/******************************************************************************/
/* Global Constants, Macros and Type Definitions                              */
/******************************************************************************/
typedef enum {
	THERM_CH_1 = 0,
	THERM_CH_2,
	THERM_CH_3,
	THERM_CH_4,
	TOTAL_THERM_CH
} thermistor_channel_t;

typedef enum {
	ANALOG_CH_1 = 0,
	ANALOG_CH_2,
	ANALOG_CH_3,
	ANALOG_CH_4,
	TOTAL_ANALOG_CH
} analog_channel_t;

/* Sensor configuration */
#define ANALOG_INPUTS_MAX_PRESSURE_SENSORS 2
#define ANALOG_INPUTS_MAX_PRESSURE_SENSORS_WITH_ULTRASONIC 1
#define ANALOG_INPUTS_MAX_ULTRASONIC 1
#define ANALOG_INPUT_NUMBER_OF_CHANNELS 4

/* RTC timestamps are printed in HH:MM:SS format (extra character for NULL) */
#define SENSOR_TASK_RTC_TIMESTAMP_SIZE 9

/******************************************************************************/
/* Global Function Prototypes                                                 */
/******************************************************************************/
/**
 * @brief The setup of the thread parameters
 */
void SensorTask_Initialize(void);

/**
 * @brief Loads updated lock code from attribute to local object
 */
void LoadSettingPasscode(void);

/**
 * @brief Converts the RTC time to a meaningful time string.
 *
 * @param [out] The converted RTC time.
 */
#ifdef CONFIG_LOG
void SensorTask_GetTimeString(uint8_t *time_string);
#else
#define SensorTask_GetTimeString(x)
#endif

#ifdef __cplusplus
}
#endif

#endif /* __SENSOR_TASK_H__ */
```

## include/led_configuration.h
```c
/**
 * @file led_configuration.h
 * @brief The BT6xx has a red + green LED.
 *
 * Copyright (c) 2020 Laird Connectivity
 *
 * SPDX-License-Identifier: Apache-2.0
 */
#ifndef __LED_CONFIGURATION_H__
#define __LED_CONFIGURATION_H__

/******************************************************************************/
/* Includes                                                                   */
/******************************************************************************/
#include "lcz_led.h"

#ifdef __cplusplus
extern "C" {
#endif

/******************************************************************************/
/* Board definitions                                                          */
/******************************************************************************/

enum led_index { GREEN_LED, RED_LED };

#ifdef __cplusplus
}
#endif

#endif /* __LED_CONFIGURATION_H__ */
```

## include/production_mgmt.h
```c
/**
 * @file production_mgmt.h
 * @brief
 *
 * Copyright (c) 2020 Laird Connectivity
 *
 * SPDX-License-Identifier: Apache-2.0
 */

#ifndef __PRODUCTION_MGMT_H__
#define __PRODUCTION_MGMT_H__

#ifdef __cplusplus
extern "C" {
#endif

/******************************************************************************/
/* Includes                                                                   */
/******************************************************************************/
#include "mgmt/mgmt.h"

/******************************************************************************/
/* Global Constants, Macros and Type Definitions                              */
/******************************************************************************/

#define MGMT_GROUP_ID_PRODUCTION_CMD 256
/* clang-format off */
#define PRODUCTION_MGMT_ID_REV_ECHO                              1
#define PRODUCTION_MGMT_ID_CALIBRATE_THERMISTOR                  2
#define PRODUCTION_MGMT_ID_TEST_LED                              3
/* clang-format on */

/******************************************************************************/
/* Global Function Prototypes                                                 */
/******************************************************************************/
#ifdef __cplusplus
}
#endif

#endif
```
